# CSI1B_RECEIVER register map
Vendor: Texas Instruments
Peripheral module from a debugger description file (folder omap34xx).
Registers are 32-bit, read-write, reset 0x0 unless marked. A register's access mark holds for its fields unless they carry their own. Offsets are as the file gives them; lines under a group give offsets from that group; [hi:lo] are bit positions; {n}, {i} and the like mark numbered series; 'fields as' and 'values as' point back to an identical list; <NAME> marks a mode.

## CSI1B_RECEIVER
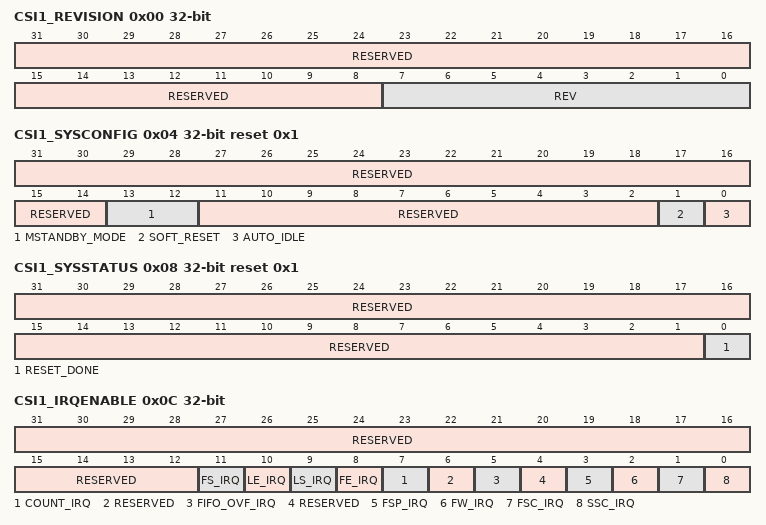
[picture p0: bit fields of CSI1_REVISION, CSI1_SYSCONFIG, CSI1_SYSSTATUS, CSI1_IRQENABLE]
0x00 CSI1_REVISION ro (reset mask 0xFFFFFF00) — MODULE REVISION This register contains the IP revision code in binary coded digital. For example, we have: 0x01 = revision 0.1 and 0x21 = revision 2.1
  [31:8] RESERVED — Write 0s for future compatibility.Reads returns 0.
  [7:0] REV — IP revision[7:4] Major revision[3:0] Minor revision
0x04 CSI1_SYSCONFIG reset 0x1 — SYSTEM CONFIGURATION REGISTER This register is the CSI1 system configuration register.
  [31:14] RESERVED — Write 0s for future compatibility.Reads returns 0.
  [13:12] MSTANDBY_MODE — Sets the behavior of the master port power management signals.
  [11:2] RESERVED — Write 0s for future compatibility.Reads returns 0.
  [1] SOFT_RESET — Software reset. Set the bit to 1 to trigger a module reset. The bit is automatically reset by the HW. During reads return 0.
  [0] AUTO_IDLE — Internal interface clock gating strategy.
0x08 CSI1_SYSSTATUS ro reset 0x1 — SYSTEM STATUS REGISTER This register provides status information about the module, excluding the interrupt status register.
  [31:1] RESERVED — Write 0s for future compatibility.Reads returns 0.
  [0] RESET_DONE — Internal reset monitoring
0x0C CSI1_IRQENABLE — INTERRUPT ENABLE REGISTER
  [31:12] RESERVED — Write 0s for future compatibility.Reads returns 0.
  [11] FS_IRQ — Frame start sync code detection.
  [10] LE_IRQ — Line end sync code detection.
  [9] LS_IRQ — Line start sync code detection.
  [8] FE_IRQ — Frame end sync code detection.
  [7] COUNT_IRQ — Frame counter reached.
  [6] RESERVED — Write 0s for future compatibility.Reads returns 0.
  [5] FIFO_OVF_IRQ — FIFO overflow error.
  [4] RESERVED — Write 0s for future compatibility.Reads returns 0.
  [3] FSP_IRQ — FSP error.
  [2] FW_IRQ — Frame width error.
  [1] FSC_IRQ — False sync code error.
  [0] SSC_IRQ — Shifted sync code error.This interrupt cannot be triggered if the complex I/O is set in parallel mode (.IO_OUT_SEL = 1).
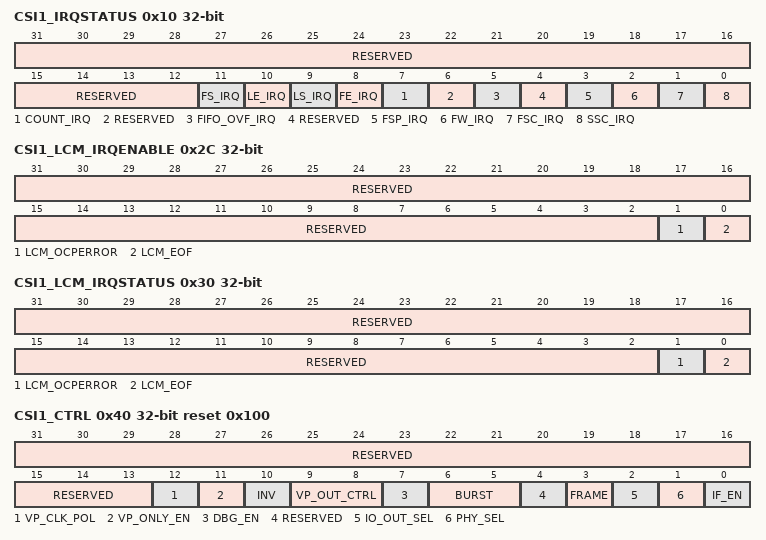
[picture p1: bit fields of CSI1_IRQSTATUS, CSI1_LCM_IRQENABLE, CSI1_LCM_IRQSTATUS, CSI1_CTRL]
0x10 CSI1_IRQSTATUS access not given — INTERRUPT STATUS REGISTER
  [31:12] RESERVED rw — Write 0s for future compatibility.Reads returns 0.
  [11] FS_IRQ — Frame start sync code detection status. (access RW1toClr)
  [10] LE_IRQ — Line end sync code detection status. (access RW1toClr)
  [9] LS_IRQ — Line start sync code detection status. (access RW1toClr)
  [8] FE_IRQ — Frame end sync code detection status. (access RW1toClr)
  [7] COUNT_IRQ — Frame counter reached status (access RW1toClr)
  [6] RESERVED — Write 0s for future compatibility.Reads returns 0. (access RW1toClr)
  [5] FIFO_OVF_IRQ — FIFO overflow error status. (access RW1toClr)
  [4] RESERVED — Write 0s for future compatibility.Reads returns 0. (access RW1toClr)
  [3] FSP_IRQ — FSP error status. (access RW1toClr)
  [2] FW_IRQ — Frame width error status. (access RW1toClr)
  [1] FSC_IRQ — False sync code error status. (access RW1toClr)
  [0] SSC_IRQ — Shifted sync code error status. (access RW1toClr)
0x2C CSI1_LCM_IRQENABLE — INTERRUPT ENABLE REGISTER - Memory channel This register regroups all the events related to the memory channel 2. The events related to memory channel trigger SINTERRUPTN[8]. The channel must be enabled for events to be generated on that channel.
  [31:2] RESERVED — Write 0s for future compatibility.Reads returns 0.
  [1] LCM_OCPERROR — An OCP error occurred on the master read port.
  [0] LCM_EOF — Memory read channel - End of frame
0x30 CSI1_LCM_IRQSTATUS access not given — INTERRUPT STATUS REGISTER - Memory channel This register regroups all the events related to memory channel. The events related to memory channel trigger SINTERRUPTN[8]. The channel must be enabled for events to be generated on that channel.
  [31:2] RESERVED rw — Write 0s for future compatibility.Reads returns 0.
  [1] LCM_OCPERROR — An OCP error occurred on the master read port. (access RW 1toClr)
  [0] LCM_EOF — Memory read channel - End of frame (access RW 1toClr)
0x40 CSI1_CTRL reset 0x100 — GLOBAL CONTROL REGISTER This register controls the CSI1 RECEIVER module. This register must not be modified dynamically (except IF_EN bit field).
  [31:13] RESERVED — Write 0s for future compatibility.Reads returns 0.
  [12] VP_CLK_POL — VP clock polarity
  [11] VP_ONLY_EN — VP only enable.
  [10] INV — Strobe/clock inversion control signal
  [9:8] VP_OUT_CTRL — Video port output clock control.Sets the video port output clock as a function of the interface clock (OCPCLK).
  [7] DBG_EN — Enables the debug mode.
  [6:5] BURST — Forces the write burst size used by the module.The write burst size must never exceed the output FIFO size. The output FIFO size can be read with the.FIFODEPTH bit field.
  [4] RESERVED — Write 0s for future compatibility.Reads returns 0.
  [3] FRAME — Set the modality in which IF_EN works.
  [2] IO_OUT_SEL — I/O cell output mode selection.
  [1] PHY_SEL — Physical layer protocol selection.
  [0] IF_EN — Enables the physical interface to the module.
0x44 CSI1_DBG wo — DEBUG REGISTER This register provides a way to debug the CSI1 RECEIVER module with no image sensor connected to the module. The debug mode is enabled by.DBG_EN. Only full 32-bit values must be written.
  [31:0] DBG — 32-bit input value.
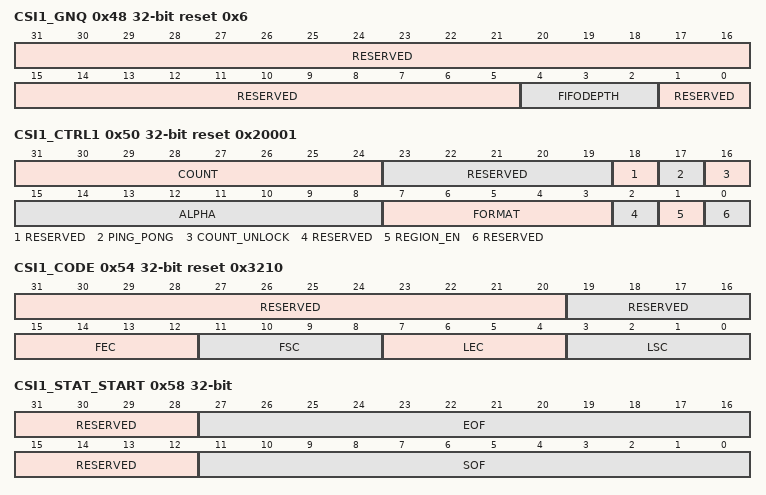
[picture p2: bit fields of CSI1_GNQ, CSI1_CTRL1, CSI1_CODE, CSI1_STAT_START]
0x48 CSI1_GNQ ro reset 0x6 — GENERIC PARAMETER REGISTER This register provide a way to read the generic parameters used in the design.
  [31:5] RESERVED — Reads returns 0.
  [4:2] FIFODEPTH — Output FIFO size in multiple of 64 bits.
  [1:0] RESERVED — Read returns 2.
0x50 CSI1_CTRL1 access per field reset 0x20001 — CONTROL REGISTER This register is shadowed: modifications are taken into account after the next FSC sync code.
  [31:24] COUNT rw — Sets the number of frame to acquire. Once the frame acquisition starts, the COUNT value is decremented after every frame. When COUNT reaches 0, the COUNT_IRQ interrupt is triggered and CHAN_EN is set to 0.Writes to this bit field are controlled by the COUNT_UNLOCK bit. COUNT can be overwritten dynamically with a new count value.'0: Infinite number of frames (no count).1: 1 frame to acquire...255: 255 frames to acquire.
  [23:19] RESERVED rw — Write 0s for future compatibility.Reads returns 0.
  [18] RESERVED rw — Write 0s for future compatibility.Reads returns 0.
  [17] PING_PONG ro — Indicates whether the PING or PONG destination address (or) was used to write the last frame. This bit field toggles after every FEC sync code.
  [16] COUNT_UNLOCK wo — Unlock writes to the COUNT bit field.
  [15:8] ALPHA rw — Alpha value for RGB888 and RBG444.
  [7:3] FORMAT rw — Data format selection.
  [2] RESERVED rw — Write 0s for future compatibility.Reads returns 0.
  [1] REGION_EN rw — Enables the setting of regions of interest in the frame: SOF region, EOF region and DAT region.
  [0] RESERVED rw — Write 1 for future compatibility.Reads returns 1.
0x54 CSI1_CODE reset 0x3210 — CODE REGISTER This register sets the codes that are used in the 32-bit synchronization codes to recognize frame start, frame end, line start and line end codes. The default values are usually not supposed to be modified. Updating this register with new codes under a flowing serial transmission causes unexpected results.
  [31:20] RESERVED — Write 0s for future compatibility.Reads returns 0.
  [19:16] RESERVED — Write 0s for future compatibility.Reads returns 0.
  [15:12] FEC — End sync code identifier.The sync code identifier is located between bits 0 to 3 in the 32-bit synchronization codes.
  [11:8] FSC — Start sync code identifier.The sync code identifier is located between bits 0 to 3 in the 32-bit synchronization codes.
  [7:4] LEC — End sync code identifier.The sync code identifier is located between bits 0 to 3 in the 32-bit synchronization codes.
  [3:0] LSC — Start sync code identifier.The sync code identifier is located between bits 0 to 3 in the 32-bit synchronization codes.
0x58 CSI1_STAT_START — STATUS LINE START REGISTER This register is shadowed: modifications are taken into account after the next FSC sync code.
  [31:28] RESERVED — Write 0s for future compatibility.Reads returns 0.
  [27:16] EOF — Sets the vertical position of the EOF status lines in regards of the FSC sync code. From 0 to 4095.
  [15:12] RESERVED — Write 0s for future compatibility.Reads returns 0.
  [11:0] SOF — Sets the vertical position of the EOF status lines in regards of the FSC sync code. Should always be 0.
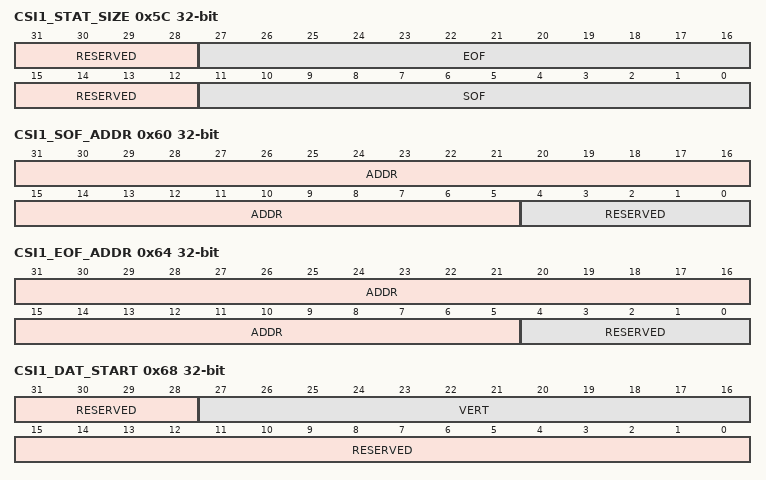
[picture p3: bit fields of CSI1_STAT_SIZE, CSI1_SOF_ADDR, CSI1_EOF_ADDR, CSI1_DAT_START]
0x5C CSI1_STAT_SIZE — STATUS LINE SIZE REGISTER This register is shadowed: modifications are taken into account after the next FSC sync code.
  [31:28] RESERVED — Write 0s for future compatibility.Reads returns 0.
  [27:16] EOF — Sets the number of EOF status linesFrom 0 to 4095
  [15:12] RESERVED — Write 0s for future compatibility.Reads returns 0.
  [11:0] SOF — Sets the number of SOF status line(s)From 0 to 4095
0x60 CSI1_SOF_ADDR — SOF STATUS LINE MEM ADDRESS REGISTER This register sets the 32-bit memory address where the SOF data are stored. Note that the 5 LSBs are ignored: the address should be aligned on a 32-byte boundary. This register is shadowed: modifications are taken into account after the next FSC sync code.
  [31:5] ADDR — 27 most significant bits of the 32-bit address.
  [4:0] RESERVED — 5 least significant bits of the 32-bit address.Write 0s for future compatibility.Reads returns 0.
0x64 CSI1_EOF_ADDR — EOF STATUS LINE MEM ADDRESS REGISTER This register sets the 32-bit memory address where the EOF data are stored. Note that the 5 LSBs are ignored: the address should be aligned on a 32-byte boundary. This register is shadowed: modifications are taken into account after the next FSC sync code.
  fields as CSI1_SOF_ADDR
0x68 CSI1_DAT_START — DATA START REGISTER This register is shadowed: modifications are taken into account after the next FSC sync code.
  [31:28] RESERVED — Write 0s for future compatibility.Reads returns 0.
  [27:16] VERT — Sets the vertical position of the data in regards of the FSC sync code. From 0 to 4095 lines.
  [15:0] RESERVED — Write 0s for future compatibility.Reads returns 0.
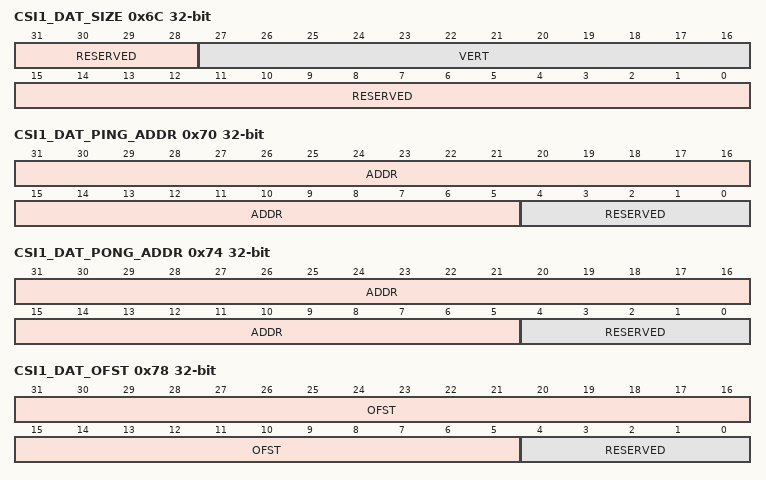
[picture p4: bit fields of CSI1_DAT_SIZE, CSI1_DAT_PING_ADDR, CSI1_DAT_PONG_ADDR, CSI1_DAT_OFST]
0x6C CSI1_DAT_SIZE — DATA SIZE REGISTER This register is shadowed: modifications are taken into account after the next FSC sync code.
  [31:28] RESERVED — Write 0s for future compatibility.Reads returns 0.
  [27:16] VERT — Sets the vertical size of the data window.From 0 to 4095 lines. If VERT = '0', no data is output.
  [15:0] RESERVED — Write 0s for future compatibility.Reads returns 0.
0x70 CSI1_DAT_PING_ADDR — DATA MEM PING ADDRESS REGISTER This register sets the 32-bit memory address where the pixel data are stored. The destination is double buffered: this register sets the PING address. Double buffering is enabled when the addressesandare different. Note that the 5 LSBs are ignored: the address should be aligned on a 32-byte boundary. This register is shadowed: modifications are taken into account after the next FSC sync code.
  fields as CSI1_SOF_ADDR
0x74 CSI1_DAT_PONG_ADDR — DATA MEM PONG ADDRESS REGISTER - LOG CHAN 0 This register sets the 32-bit memory address where the pixel data are stored. The destination is double buffered: this register sets the PONG address. Double buffering is enabled when the addressesandare different. Note that the 5 LSBs are ignored: the address should be aligned on a 32-byte boundary. This register is shadowed: modifications are taken into account after the next FSC sync code.
  fields as CSI1_SOF_ADDR
0x78 CSI1_DAT_OFST — DATA MEM ADDRESS OFFSET REGISTER This register sets the offset, which is applied on the destination address after each line is written to memory. This register applies for bothand. For example, it enables to perform 2D data transfers of the pixel data into a frame buffer. In such case, the pixel data and frame buffer data must have the same data format. Note that the 5 LSBs are ignored: the offset must be a multiple of 32 bytes. The usage of this register is limited to the following data formats: YUV422 LITTLE ENDIAN, YUV422 BIG ENDIAN, RGB565, RGB444 + EXP16, RGB888 + EXP32. This register is shadowed: modifications are taken into account after the next FSC sync code.
  [31:5] OFST — Line offset programmed in bytes.If OFST = 0, the data is written contiguously in memory. Otherwise, OFST sets the destination offset between the first pixel of the previous line and the first pixel of the current line.
  [4:0] RESERVED — Write 0s for future compatibility.Reads returns 0.
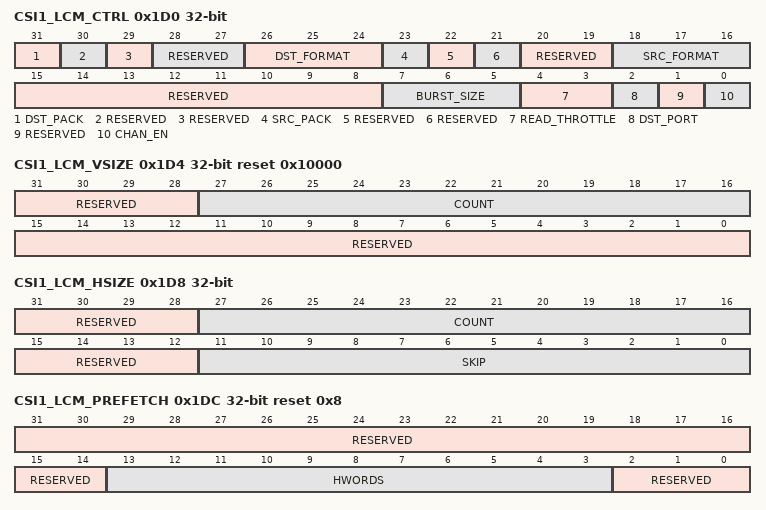
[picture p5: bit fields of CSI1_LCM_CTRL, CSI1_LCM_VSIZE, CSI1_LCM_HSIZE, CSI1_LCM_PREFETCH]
0x1D0 CSI1_LCM_CTRL — Control register for the memory channel. It defines the data format of the source frame stored in memory and how this frame is processed.
  [31] DST_PACK — Data is packed before it's send to memory.
  [30] RESERVED — Write 0s for future compatibility.Reads returns 0.
  [29] RESERVED — Write 0s for future compatibility.Reads returns 0.
  [28:27] RESERVED — Write 0s for future compatibility.Reads returns 0.
  [26:24] DST_FORMAT — Output format selection.Not every combination between input and output formats are possible. Check the specification for allowed modes.
  [23] SRC_PACK — Data stored in memory is packed and must be unpacked.
  [22] RESERVED — Write 0s for future compatibility.Reads returns 0.
  [21] RESERVED — Write 0s for future compatibility.Reads returns 0.
  [20:19] RESERVED — Write 0s for future compatibility.Reads returns 0.
  [18:16] SRC_FORMAT — Data format of the data stored in memory.As there is no header embedded in the data sent to memory, users are responsible of choosing the proper format.
  [15:8] RESERVED — Write 0s for future compatibility.Reads returns 0.
  [7:5] BURST_SIZE — Defines the burst size of the master read port
  [4:3] READ_THROTTLE — Limit maximum data read speed for memory to memory operation
  [2] DST_PORT — Select the destination port
  [1] RESERVED — Write 0s for future compatibility.Reads returns 0.
  [0] CHAN_EN — Enables the read from memory channel.Before enabling the memory read channel SW must:- disable the physical interface using the IF_EN bit- wait until disabling of the physical interface is effective (depends on the FRAME bit)Read from memory starts as soon as this bit is set, therefore all CSI1_LCM_x registers must be configured correctly before.This bit is cleared by HW at the end of the frame.
0x1D4 CSI1_LCM_VSIZE reset 0x10000 — Memory channel vertical framing register
  [31:28] RESERVED — Write 0s for future compatibility.Reads returns 0.
  [27:16] COUNT — Defines the line count to be read from memory.From 1 to 4095 lines.
  [15:0] RESERVED — Write 0s for future compatibility.Reads returns 0.
0x1D8 CSI1_LCM_HSIZE — Memory read channel horizontal framing register.
  [31:28] RESERVED — Write 0s for future compatibility.Reads returns 0.
  [27:16] COUNT — Horizontal count of pixels to output after the skipped pixels.Valid values: 1-4095.
  [15:12] RESERVED — Write 0s for future compatibility.Reads returns 0.
  [11:0] SKIP — Horizontal count of pixels to skip after the start of the line.Valid values: 0-4095.0 disables pixel skipping
0x1DC CSI1_LCM_PREFETCH reset 0x8 — This register defines the amount of data to be fetched from memory. Is must be consistent with theregister (check programing model)
  [31:14] RESERVED — Write 0s for future compatibility.Reads returns 0.
  [13:3] HWORDS — 64 bit words to read from memory for each line of the image.Possible values 1..2047
  [2:0] RESERVED — Write 0s for future compatibility.Reads returns 0.
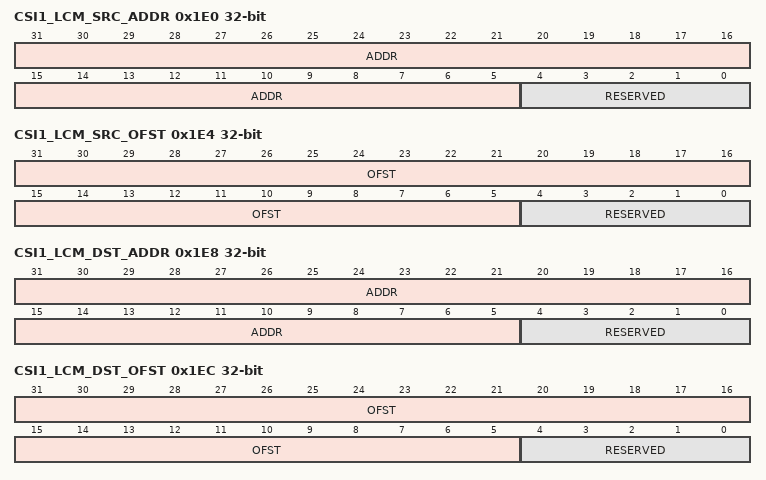
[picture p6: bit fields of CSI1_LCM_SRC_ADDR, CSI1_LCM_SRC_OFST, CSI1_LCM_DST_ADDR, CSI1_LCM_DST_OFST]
0x1E0 CSI1_LCM_SRC_ADDR — Memory channel source address register This register sets the 32-bit memory address where the pixel data are stored. Note that the 5 LSBs are ignored: the address should be aligned on a 32-byte boundary.
  fields as CSI1_SOF_ADDR
0x1E4 CSI1_LCM_SRC_OFST — Memory channel source offset register. This register sets the offset, which is applied on the source address after each line is read from memory. For example, it enables to perform 2D data transfers of the pixel data from a frame buffer. In such case, the pixel data and frame buffer data must have the same data format. Note that the 5 LSBs are ignored: the offset must be a multiple of 32 bytes.
  [31:5] OFST — Line offset programmed in bytes.If OFST = 0, the data is read contiguously from memory. Otherwise, OFST sets the source offset between the first pixel of the previous line and the first pixel of the current line.
  [4:0] RESERVED — Write 0s for future compatibility.Reads returns 0.
0x1E8 CSI1_LCM_DST_ADDR — Memory channel destination address. This register sets the 32-bit memory address where the pixel data are stored. Note that the 5 LSBs are ignored: the address should be aligned on a 32-byte boundary.
  fields as CSI1_SOF_ADDR
0x1EC CSI1_LCM_DST_OFST — Memory channel destination offset register. This register sets the offset, which is applied on the destination address after each line is written to memory. For example, it enables to perform 2D data transfers of the pixel data into a frame buffer. In such case, the pixel data and frame buffer data must have the same data format. Note that the 5 LSBs are ignored: the offset must be a multiple of 32 bytes.
  [31:5] OFST — Line offset programmed in bytes.If OFST = 0, the data is written contiguously to memory if possible. At the end of a line only full 32 bit words are written, creating eventually gaps at the end of lines.Otherwise, OFST sets the destination offset between the first pixel of the previous line and the first pixel of the current line.
  [4:0] RESERVED — Write 0s for future compatibility.Reads returns 0.
